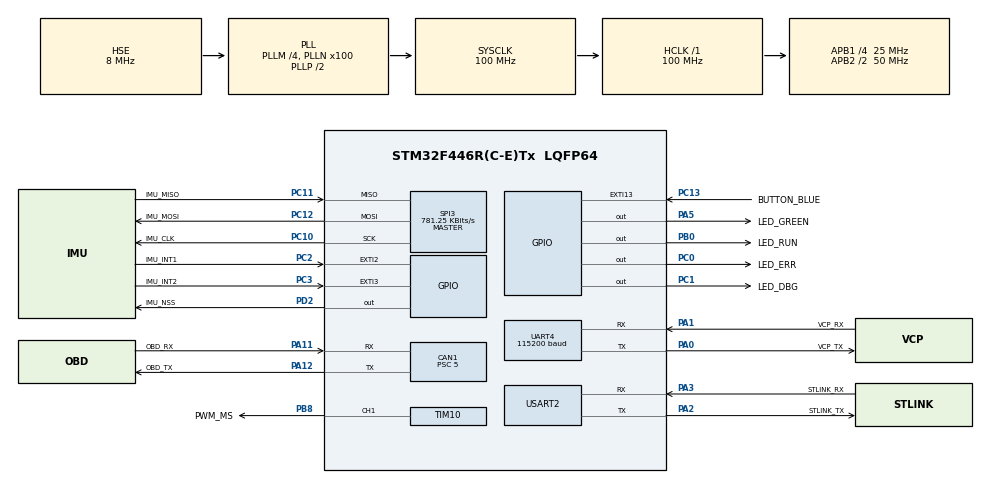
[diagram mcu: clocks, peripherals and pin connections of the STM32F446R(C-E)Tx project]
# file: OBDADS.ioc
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CAN1.BS1=CAN_BS1_8TQ
CAN1.CalculateBaudRate=500000
CAN1.CalculateTimeBit=2000
CAN1.CalculateTimeQuantum=200.0
CAN1.NART=ENABLE
CAN1.Prescaler=5
CAN1.SJW=CAN_SJW_1TQ
Dma.Request0=UART4_TX
Dma.Request1=UART4_RX
Dma.Request2=USART2_TX
Dma.Request3=USART2_RX
Dma.Request4=SPI3_TX
Dma.Request5=SPI3_RX
Dma.SPI3_RX.5.Direction=DMA_PERIPH_TO_MEMORY
Dma.SPI3_RX.5.FIFOMode=DMA_FIFOMODE_DISABLE
Dma.SPI3_RX.5.Instance=DMA1_Stream0
Dma.SPI3_RX.5.MemDataAlignment=DMA_MDATAALIGN_BYTE
Dma.SPI3_RX.5.MemInc=DMA_MINC_ENABLE
Dma.SPI3_RX.5.Mode=DMA_NORMAL
Dma.SPI3_RX.5.PeriphDataAlignment=DMA_PDATAALIGN_BYTE
Dma.SPI3_RX.5.PeriphInc=DMA_PINC_DISABLE
Dma.SPI3_RX.5.Priority=DMA_PRIORITY_LOW
Dma.SPI3_TX.4.Direction=DMA_MEMORY_TO_PERIPH
Dma.SPI3_TX.4.FIFOMode=DMA_FIFOMODE_DISABLE
Dma.SPI3_TX.4.Instance=DMA1_Stream7
Dma.SPI3_TX.4.MemDataAlignment=DMA_MDATAALIGN_BYTE
Dma.SPI3_TX.4.MemInc=DMA_MINC_ENABLE
Dma.SPI3_TX.4.Mode=DMA_NORMAL
Dma.SPI3_TX.4.PeriphDataAlignment=DMA_PDATAALIGN_BYTE
Dma.SPI3_TX.4.PeriphInc=DMA_PINC_DISABLE
Dma.SPI3_TX.4.Priority=DMA_PRIORITY_LOW
Dma.UART4_RX.1.Direction=DMA_PERIPH_TO_MEMORY
Dma.UART4_RX.1.FIFOMode=DMA_FIFOMODE_DISABLE
Dma.UART4_RX.1.Instance=DMA1_Stream2
Dma.UART4_RX.1.MemDataAlignment=DMA_MDATAALIGN_BYTE
Dma.UART4_RX.1.MemInc=DMA_MINC_ENABLE
Dma.UART4_RX.1.Mode=DMA_NORMAL
Dma.UART4_RX.1.PeriphDataAlignment=DMA_PDATAALIGN_BYTE
Dma.UART4_RX.1.PeriphInc=DMA_PINC_DISABLE
Dma.UART4_RX.1.Priority=DMA_PRIORITY_LOW
Dma.UART4_TX.0.Direction=DMA_MEMORY_TO_PERIPH
Dma.UART4_TX.0.FIFOMode=DMA_FIFOMODE_DISABLE
Dma.UART4_TX.0.Instance=DMA1_Stream4
Dma.UART4_TX.0.MemDataAlignment=DMA_MDATAALIGN_BYTE
Dma.UART4_TX.0.MemInc=DMA_MINC_ENABLE
Dma.UART4_TX.0.Mode=DMA_NORMAL
Dma.UART4_TX.0.PeriphDataAlignment=DMA_PDATAALIGN_BYTE
Dma.UART4_TX.0.PeriphInc=DMA_PINC_DISABLE
Dma.UART4_TX.0.Priority=DMA_PRIORITY_LOW
Dma.USART2_RX.3.Direction=DMA_PERIPH_TO_MEMORY
Dma.USART2_RX.3.FIFOMode=DMA_FIFOMODE_DISABLE
Dma.USART2_RX.3.Instance=DMA1_Stream5
Dma.USART2_RX.3.MemDataAlignment=DMA_MDATAALIGN_BYTE
Dma.USART2_RX.3.MemInc=DMA_MINC_ENABLE
Dma.USART2_RX.3.Mode=DMA_NORMAL
Dma.USART2_RX.3.PeriphDataAlignment=DMA_PDATAALIGN_BYTE
Dma.USART2_RX.3.PeriphInc=DMA_PINC_DISABLE
Dma.USART2_RX.3.Priority=DMA_PRIORITY_LOW
Dma.USART2_TX.2.Direction=DMA_MEMORY_TO_PERIPH
Dma.USART2_TX.2.FIFOMode=DMA_FIFOMODE_DISABLE
Dma.USART2_TX.2.Instance=DMA1_Stream6
Dma.USART2_TX.2.MemDataAlignment=DMA_MDATAALIGN_BYTE
Dma.USART2_TX.2.MemInc=DMA_MINC_ENABLE
Dma.USART2_TX.2.Mode=DMA_NORMAL
Dma.USART2_TX.2.PeriphDataAlignment=DMA_PDATAALIGN_BYTE
Dma.USART2_TX.2.PeriphInc=DMA_PINC_DISABLE
Dma.USART2_TX.2.Priority=DMA_PRIORITY_LOW
Mcu.Family=STM32F4
Mcu.Name=STM32F446R(C-E)Tx
Mcu.Package=LQFP64
NVIC.CAN1_RX0_IRQn=true\:0\:0\:false\:false\:true\:true\:true\:true
NVIC.CAN1_RX1_IRQn=true\:0\:0\:false\:false\:true\:true\:true\:true
NVIC.CAN1_TX_IRQn=true\:0\:0\:false\:false\:true\:true\:true\:true
NVIC.DMA1_Stream0_IRQn=true\:0\:0\:false\:false\:true\:false\:true\:true
NVIC.DMA1_Stream2_IRQn=true\:0\:0\:false\:false\:true\:false\:true\:true
NVIC.DMA1_Stream4_IRQn=true\:0\:0\:false\:false\:true\:false\:true\:true
NVIC.DMA1_Stream5_IRQn=true\:0\:0\:false\:false\:true\:false\:true\:true
NVIC.DMA1_Stream6_IRQn=true\:0\:0\:false\:false\:true\:false\:true\:true
NVIC.DMA1_Stream7_IRQn=true\:0\:0\:false\:false\:true\:false\:true\:true
NVIC.EXTI15_10_IRQn=true\:0\:0\:false\:false\:true\:true\:true\:true
NVIC.EXTI2_IRQn=true\:0\:0\:false\:false\:true\:true\:true\:true
NVIC.EXTI3_IRQn=true\:0\:0\:false\:false\:true\:true\:true\:true
NVIC.PriorityGroup=NVIC_PRIORITYGROUP_0
NVIC.SPI3_IRQn=true\:0\:0\:false\:false\:true\:true\:true\:true
NVIC.TIM1_UP_TIM10_IRQn=true\:0\:0\:false\:false\:true\:true\:true\:true
NVIC.UART4_IRQn=true\:0\:0\:false\:false\:true\:true\:true\:true
NVIC.USART2_IRQn=true\:0\:0\:false\:false\:true\:true\:true\:true
PA0-WKUP.GPIO_Label=VCP_TX
PA0-WKUP.Mode=Asynchronous
PA0-WKUP.Signal=UART4_TX
PA1.GPIO_Label=VCP_RX
PA1.Mode=Asynchronous
PA1.Signal=UART4_RX
PA11.GPIO_Label=OBD_RX
PA11.GPIO_PuPd=GPIO_PULLUP
PA11.Mode=CAN_Activate
PA11.Signal=CAN1_RX
PA12.GPIO_Label=OBD_TX
PA12.Mode=CAN_Activate
PA12.Signal=CAN1_TX
PA13.GPIO_Label=TMS
PA13.Mode=Serial_Wire
PA13.Signal=SYS_JTMS-SWDIO
PA14.GPIO_Label=TCK
PA14.Mode=Serial_Wire
PA14.Signal=SYS_JTCK-SWCLK
PA2.GPIO_Label=STLINK_TX
PA2.Mode=Asynchronous
PA2.Signal=USART2_TX
PA3.GPIO_Label=STLINK_RX
PA3.Mode=Asynchronous
PA3.Signal=USART2_RX
PA5.GPIO_Label=LED_GREEN
PA5.Signal=GPIO_Output
PB0.GPIO_Label=LED_RUN
PB0.Signal=GPIO_Output
PB8.GPIO_Label=PWM_MS
PB8.Signal=S_TIM10_CH1
PC0.GPIO_Label=LED_ERR
PC0.Signal=GPIO_Output
PC1.GPIO_Label=LED_DBG
PC1.Signal=GPIO_Output
PC10.GPIO_Label=IMU_CLK
PC10.Mode=Full_Duplex_Master
PC10.Signal=SPI3_SCK
PC11.GPIO_Label=IMU_MISO
PC11.Mode=Full_Duplex_Master
PC11.Signal=SPI3_MISO
PC12.GPIO_Label=IMU_MOSI
PC12.Mode=Full_Duplex_Master
PC12.Signal=SPI3_MOSI
PC13.GPIO_Label=BUTTON_BLUE
PC13.GPIO_ModeDefaultEXTI=GPIO_MODE_IT_FALLING
PC13.Signal=GPXTI13
PC14-OSC32_IN.Mode=LSE-External-Oscillator
PC14-OSC32_IN.Signal=RCC_OSC32_IN
PC15-OSC32_OUT.Mode=LSE-External-Oscillator
PC15-OSC32_OUT.Signal=RCC_OSC32_OUT
PC2.GPIO_Label=IMU_INT1
PC2.Signal=GPXTI2
PC3.GPIO_Label=IMU_INT2
PC3.Signal=GPXTI3
PD2.GPIO_Label=IMU_NSS
PD2.GPIO_Speed=GPIO_SPEED_FREQ_HIGH
PD2.PinState=GPIO_PIN_SET
PD2.Signal=GPIO_Output
PH0-OSC_IN.Mode=HSE-External-Oscillator
PH0-OSC_IN.Signal=RCC_OSC_IN
PH1-OSC_OUT.Mode=HSE-External-Oscillator
PH1-OSC_OUT.Signal=RCC_OSC_OUT
ProjectManager.HeapSize=0x200
ProjectManager.StackSize=0x400
ProjectManager.TargetToolchain=STM32CubeIDE
RCC.48MHZClocksFreq_Value=84000000
RCC.AHBFreq_Value=100000000
RCC.APB1CLKDivider=RCC_HCLK_DIV4
RCC.APB1Freq_Value=25000000
RCC.APB1TimFreq_Value=50000000
RCC.APB2CLKDivider=RCC_HCLK_DIV2
RCC.APB2Freq_Value=50000000
RCC.APB2TimFreq_Value=100000000
RCC.CortexFreq_Value=100000000
RCC.FLatency-AdvancedSettings=FLASH_LATENCY_3
RCC.HCLKFreq_Value=100000000
RCC.HSE_VALUE=8000000
RCC.HSI_VALUE=16000000
RCC.PLLM=4
RCC.PLLN=100
RCC.PLLSourceVirtual=RCC_PLLSOURCE_HSE
RCC.SYSCLKFreq_VALUE=100000000
RCC.SYSCLKSource=RCC_SYSCLKSOURCE_PLLCLK
RCC.USBFreq_Value=100000000
RCC.VCOOutputFreq_Value=200000000
SH.S_TIM10_CH1.0=TIM10_CH1,PWM Generation1 CH1
SPI3.BaudRatePrescaler=SPI_BAUDRATEPRESCALER_32
SPI3.CLKPhase=SPI_PHASE_2EDGE
SPI3.CLKPolarity=SPI_POLARITY_HIGH
SPI3.CalculateBaudRate=781.25 KBits/s
SPI3.Direction=SPI_DIRECTION_2LINES
SPI3.Mode=SPI_MODE_MASTER
SPI3.VirtualType=VM_MASTER
TIM10.Channel=TIM_CHANNEL_1
TIM10.Period=50000 - 1
TIM10.Prescaler=2 - 1
UART4.BaudRate=115200
UART4.VirtualMode=Asynchronous
USART2.VirtualMode=VM_ASYNC
VP_TIM10_VS_ClockSourceINT.Mode=Enable_Timer
board=NUCLEO-F446RE

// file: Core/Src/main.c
/* USER CODE BEGIN Header */
/**
  ******************************************************************************
  * @file           : main.c
  * @brief          : Main program body
  ******************************************************************************
  * @attention
  *
  * Copyright (c) 2025 STMicroelectronics.
  * All rights reserved.
  *
  * This software is licensed under terms that can be found in the LICENSE file
  * in the root directory of this software component.
  * If no LICENSE file comes with this software, it is provided AS-IS.
  *
  ******************************************************************************
  */
/* USER CODE END Header */
#include "main.h"
#include "can.h"
#include "dma.h"
#include "spi.h"
#include "tim.h"
#include "usart.h"
#include "gpio.h"

/* USER CODE BEGIN Includes */

#include "sys.h"

/* USER CODE END Includes */

void SystemClock_Config(void);

int main(void)
{

  /* MCU Configuration--------------------------------------------------------*/

  /* Reset of all peripherals, Initializes the Flash interface and the Systick. */
  HAL_Init();

  /* Configure the system clock */
  SystemClock_Config();

  /* Initialize all configured peripherals */
  MX_GPIO_Init();
  MX_DMA_Init();
  MX_USART2_UART_Init();
  MX_CAN1_Init();
  MX_TIM10_Init();
  MX_UART4_Init();
  MX_SPI3_Init();
  /* USER CODE BEGIN 2 */

  SysInit();

  /* USER CODE END 2 */

  /* Infinite loop */
  while (1)
  {

    /* USER CODE BEGIN 3 */
    if (ExecuteSystem == SET) {
      ExecuteSystem = RESET;
      SysExecute();
    }
  }
  /* USER CODE END 3 */
}

void SystemClock_Config(void)
{
  RCC_OscInitTypeDef RCC_OscInitStruct = {0};
  RCC_ClkInitTypeDef RCC_ClkInitStruct = {0};

  /** Configure the main internal regulator output voltage
  */
  __HAL_RCC_PWR_CLK_ENABLE();
  __HAL_PWR_VOLTAGESCALING_CONFIG(PWR_REGULATOR_VOLTAGE_SCALE3);

  /** Initializes the RCC Oscillators according to the specified parameters
  * in the RCC_OscInitTypeDef structure.
  */
  RCC_OscInitStruct.OscillatorType = RCC_OSCILLATORTYPE_HSE;
  RCC_OscInitStruct.HSEState = RCC_HSE_ON;
  RCC_OscInitStruct.PLL.PLLState = RCC_PLL_ON;
  RCC_OscInitStruct.PLL.PLLSource = RCC_PLLSOURCE_HSE;
  RCC_OscInitStruct.PLL.PLLM = 4;
  RCC_OscInitStruct.PLL.PLLN = 100;
  RCC_OscInitStruct.PLL.PLLP = RCC_PLLP_DIV2;
  RCC_OscInitStruct.PLL.PLLQ = 2;
  RCC_OscInitStruct.PLL.PLLR = 2;
  if (HAL_RCC_OscConfig(&RCC_OscInitStruct) != HAL_OK)
  {
    Error_Handler();
  }

  /** Initializes the CPU, AHB and APB buses clocks
  */
  RCC_ClkInitStruct.ClockType = RCC_CLOCKTYPE_HCLK|RCC_CLOCKTYPE_SYSCLK
                              |RCC_CLOCKTYPE_PCLK1|RCC_CLOCKTYPE_PCLK2;
  RCC_ClkInitStruct.SYSCLKSource = RCC_SYSCLKSOURCE_PLLCLK;
  RCC_ClkInitStruct.AHBCLKDivider = RCC_SYSCLK_DIV1;
  RCC_ClkInitStruct.APB1CLKDivider = RCC_HCLK_DIV4;
  RCC_ClkInitStruct.APB2CLKDivider = RCC_HCLK_DIV2;

  if (HAL_RCC_ClockConfig(&RCC_ClkInitStruct, FLASH_LATENCY_3) != HAL_OK)
  {
    Error_Handler();
  }
}

void Error_Handler(void)
{
  /* USER CODE BEGIN Error_Handler_Debug */
  /* User can add his own implementation to report the HAL error return state */
  __disable_irq();
  DwtInit();
  while (1)
  {
    HAL_GPIO_TogglePin(LED_ERR_GPIO_Port, LED_ERR_Pin);
    DwtNoOpDelay(SYS_ERROR_DELAY_MS);
  }
  /* USER CODE END Error_Handler_Debug */
}
